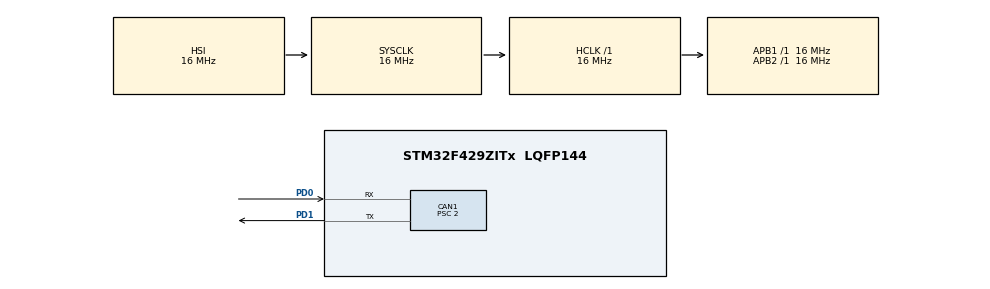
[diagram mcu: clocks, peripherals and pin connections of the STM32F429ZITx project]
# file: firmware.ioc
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CAN1.AutoBusOff=DISABLE
CAN1.AutoRetransmission=ENABLE
CAN1.AutoWakeUp=DISABLE
CAN1.BS1=CAN_BS1_13TQ
CAN1.BS2=CAN_BS2_2TQ
CAN1.CalculateBaudRate=500000
CAN1.CalculateTimeBit=2000
CAN1.CalculateTimeQuantum=125.0
CAN1.Prescaler=2
CAN1.ReceiveFifoLocked=DISABLE
CAN1.SyncJumpWidth=CAN_SJW_1TQ
CAN1.TimeTriggerMode=DISABLE
CAN1.TransmitFifoPriority=DISABLE
FREERTOS.Tasks01=defaultTask,24,128,StartDefaultTask,AS_EXTERNAL,NULL,0,defaultTaskBuffer,defaultTaskControlBlock
FREERTOS.Tasks02=canRxTask,32,256,StartCanRxTask,AS_EXTERNAL,NULL,0,canRxTaskBuffer,canRxTaskControlBlock
FREERTOS.Tasks03=canTxTask,32,256,StartCanTxTask,AS_EXTERNAL,NULL,0,canTxTaskBuffer,canTxTaskControlBlock
FREERTOS.configTOTAL_HEAP_SIZE=8192
Mcu.Family=STM32F4
Mcu.Name=STM32F429ZITx
Mcu.Package=LQFP144
NVIC.CAN1_RX0_IRQn=true\:5\:0\:true\:false\:true\:false\:true\:false\:true
NVIC.CAN1_TX_IRQn=true\:5\:0\:true\:false\:true\:false\:true\:false\:true
NVIC.PriorityGroup=NVIC_PRIORITYGROUP_4
PD0.Mode=CAN_Activate
PD0.Signal=CAN1_RX
PD1.Mode=CAN_Activate
PD1.Signal=CAN1_TX
ProjectManager.HeapSize=0x200
ProjectManager.StackSize=0x400
ProjectManager.TargetToolchain=STM32CubeIDE
RCC.AHBFreq_Value=16000000
RCC.APB1Freq_Value=16000000
RCC.APB2Freq_Value=16000000
RCC.CortexFreq_Value=16000000
RCC.HSE_VALUE=25000000
RCC.HSI_VALUE=16000000
RCC.LSE_VALUE=32768
RCC.SYSCLKFreq_VALUE=16000000
RCC.VCOOutputFreq_Value=192000000
VP_FREERTOS_VS_CMSIS_V1.Mode=CMSIS_V1
board=custom

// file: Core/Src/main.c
/* USER CODE BEGIN Header */
/**
  ******************************************************************************
  * @file           : main.c
  * @brief          : Main program body
  ******************************************************************************
  * @attention
  *
  * Copyright (c) 2026 STMicroelectronics.
  * All rights reserved.
  *
  * This software is licensed under terms that can be found in the LICENSE file
  * in the root directory of this software component.
  * If no LICENSE file comes with this software, it is provided AS-IS.
  *
  ******************************************************************************
  */
/* USER CODE END Header */
#include "main.h"
#include "cmsis_os.h"

/* USER CODE BEGIN Includes */
#include "queue.h"
/* USER CODE END Includes */

/* USER CODE BEGIN PTD */
/**
 * @brief  CAN frame descriptor exchanged through the inter-task queue.
 */
typedef struct
{
    uint32_t id;       /**< Standard (11-bit) or extended (29-bit) CAN ID */
    uint8_t  ide;      /**< 0 = standard, 1 = extended */
    uint8_t  dlc;      /**< Data-length code (0–8 bytes) */
    uint8_t  data[8];  /**< Payload */
} CAN_Msg_t;
/* USER CODE END PTD */

/* USER CODE BEGIN PD */
/** Number of CAN_Msg_t slots held in the receive queue */
#define CAN_QUEUE_LEN  10U
/** TX frame CAN standard ID */
#define CAN_TX_STD_ID  0x123U
/* USER CODE END PD */

CAN_HandleTypeDef hcan1;

osThreadId defaultTaskHandle;
uint32_t defaultTaskBuffer[ 128 ];
osStaticThreadDef_t defaultTaskControlBlock;
osThreadId canRxTaskHandle;
uint32_t canRxTaskBuffer[ 256 ];
osStaticThreadDef_t canRxTaskControlBlock;
/* USER CODE BEGIN PV */
/* ------------ CAN RX queue (ISR → canRxTask) ----------------------------- */
static QueueHandle_t canRxQueue;
static StaticQueue_t canRxQueueStruct;
static uint8_t       canRxQueueStorage[CAN_QUEUE_LEN * sizeof(CAN_Msg_t)];

osThreadId canTxTaskHandle;
uint32_t canTxTaskBuffer[ 256 ];
osStaticThreadDef_t canTxTaskControlBlock;
/* USER CODE END PV */

void SystemClock_Config(void);
static void MX_GPIO_Init(void);
static void MX_CAN1_Init(void);
void StartDefaultTask(void const * argument);
void StartCanRxTask(void const * argument);

/* USER CODE BEGIN PFP */
void StartCanTxTask(void const * argument);
/* USER CODE END PFP */

int main(void)
{

  /* MCU Configuration--------------------------------------------------------*/

  /* Reset of all peripherals, Initializes the Flash interface and the Systick. */
  HAL_Init();

  /* Configure the system clock */
  SystemClock_Config();

  /* Initialize all configured peripherals */
  MX_GPIO_Init();
  MX_CAN1_Init();

  /* USER CODE BEGIN RTOS_QUEUES */
  /* Create the RX queue with statically-allocated storage */
  canRxQueue = xQueueCreateStatic(CAN_QUEUE_LEN,
                                   sizeof(CAN_Msg_t),
                                   canRxQueueStorage,
                                   &canRxQueueStruct);
  configASSERT(canRxQueue != NULL);

  /* Enable RX-FIFO0 interrupt now that the queue exists */
  if (HAL_CAN_ActivateNotification(&hcan1, CAN_IT_RX_FIFO0_MSG_PENDING) != HAL_OK)
  {
    Error_Handler();
  }
  /* USER CODE END RTOS_QUEUES */

  /* Create the thread(s) */
  /* definition and creation of defaultTask */
  osThreadStaticDef(defaultTask, StartDefaultTask, osPriorityNormal, 0, 128, defaultTaskBuffer, &defaultTaskControlBlock);
  defaultTaskHandle = osThreadCreate(osThread(defaultTask), NULL);

  /* definition and creation of canRxTask */
  osThreadStaticDef(canRxTask, StartCanRxTask, osPriorityNormal, 0, 256, canRxTaskBuffer, &canRxTaskControlBlock);
  canRxTaskHandle = osThreadCreate(osThread(canRxTask), NULL);

  /* USER CODE BEGIN RTOS_THREADS */
  /* Create canTxTask through CMSIS-RTOS, matching firmware.ioc and the other tasks. */
  osThreadStaticDef(canTxTask, StartCanTxTask, osPriorityAboveNormal, 0, 256,
                    canTxTaskBuffer, &canTxTaskControlBlock);
  canTxTaskHandle = osThreadCreate(osThread(canTxTask), NULL);
  configASSERT(canTxTaskHandle != NULL);
  /* USER CODE END RTOS_THREADS */

  /* Start scheduler */
  osKernelStart();

  /* We should never get here as control is now taken by the scheduler */

  /* Infinite loop */
  while (1)
  {

  }
}

void SystemClock_Config(void)
{
  RCC_OscInitTypeDef RCC_OscInitStruct = {0};
  RCC_ClkInitTypeDef RCC_ClkInitStruct = {0};

  /** Configure the main internal regulator output voltage
  */
  __HAL_RCC_PWR_CLK_ENABLE();
  __HAL_PWR_VOLTAGESCALING_CONFIG(PWR_REGULATOR_VOLTAGE_SCALE3);

  /** Initializes the RCC Oscillators according to the specified parameters
  * in the RCC_OscInitTypeDef structure.
  */
  RCC_OscInitStruct.OscillatorType = RCC_OSCILLATORTYPE_HSI;
  RCC_OscInitStruct.HSIState = RCC_HSI_ON;
  RCC_OscInitStruct.HSICalibrationValue = RCC_HSICALIBRATION_DEFAULT;
  RCC_OscInitStruct.PLL.PLLState = RCC_PLL_NONE;
  if (HAL_RCC_OscConfig(&RCC_OscInitStruct) != HAL_OK)
  {
    Error_Handler();
  }

  /** Initializes the CPU, AHB and APB buses clocks
  */
  RCC_ClkInitStruct.ClockType = RCC_CLOCKTYPE_HCLK|RCC_CLOCKTYPE_SYSCLK
                              |RCC_CLOCKTYPE_PCLK1|RCC_CLOCKTYPE_PCLK2;
  RCC_ClkInitStruct.SYSCLKSource = RCC_SYSCLKSOURCE_HSI;
  RCC_ClkInitStruct.AHBCLKDivider = RCC_SYSCLK_DIV1;
  RCC_ClkInitStruct.APB1CLKDivider = RCC_HCLK_DIV1;
  RCC_ClkInitStruct.APB2CLKDivider = RCC_HCLK_DIV1;

  if (HAL_RCC_ClockConfig(&RCC_ClkInitStruct, FLASH_LATENCY_0) != HAL_OK)
  {
    Error_Handler();
  }
}

static void MX_CAN1_Init(void)
{

  hcan1.Instance = CAN1;
  hcan1.Init.Prescaler = 2;
  hcan1.Init.Mode = CAN_MODE_NORMAL;
  hcan1.Init.SyncJumpWidth = CAN_SJW_1TQ;
  hcan1.Init.TimeSeg1 = CAN_BS1_13TQ;
  hcan1.Init.TimeSeg2 = CAN_BS2_2TQ;
  hcan1.Init.TimeTriggeredMode = DISABLE;
  hcan1.Init.AutoBusOff = DISABLE;
  hcan1.Init.AutoWakeUp = DISABLE;
  hcan1.Init.AutoRetransmission = DISABLE;
  hcan1.Init.ReceiveFifoLocked = DISABLE;
  hcan1.Init.TransmitFifoPriority = DISABLE;
  if (HAL_CAN_Init(&hcan1) != HAL_OK)
  {
    Error_Handler();
  }
  /* USER CODE BEGIN CAN1_Init 2 */
  /* Accept-all pass-through filter → FIFO0 */
  {
    CAN_FilterTypeDef sFilter = {0};
    sFilter.FilterBank           = 0;
    sFilter.FilterMode           = CAN_FILTERMODE_IDMASK;
    sFilter.FilterScale          = CAN_FILTERSCALE_32BIT;
    sFilter.FilterIdHigh         = 0x0000U;
    sFilter.FilterIdLow          = 0x0000U;
    sFilter.FilterMaskIdHigh     = 0x0000U; /* mask 0 = accept all */
    sFilter.FilterMaskIdLow      = 0x0000U;
    sFilter.FilterFIFOAssignment = CAN_RX_FIFO0;
    sFilter.FilterActivation     = ENABLE;
    if (HAL_CAN_ConfigFilter(&hcan1, &sFilter) != HAL_OK) { Error_Handler(); }
  }
  if (HAL_CAN_Start(&hcan1) != HAL_OK) { Error_Handler(); }
  /* USER CODE END CAN1_Init 2 */

}

static void MX_GPIO_Init(void)
{

  /* GPIO Ports Clock Enable */
  __HAL_RCC_GPIOD_CLK_ENABLE();

}

/* USER CODE BEGIN 4 */

/**
 * @brief  CAN RX FIFO0 message-pending callback (called from ISR context).
 *
 *         Reads the incoming frame from the hardware and posts a CAN_Msg_t to
 *         canRxQueue so that StartCanRxTask can process it at task level.
 */
void HAL_CAN_RxFifo0MsgPendingCallback(CAN_HandleTypeDef *hcan)
{
  CAN_RxHeaderTypeDef rxHdr;
  CAN_Msg_t           msg;
  BaseType_t          xHigherPriorityTaskWoken = pdFALSE;

  if (HAL_CAN_GetRxMessage(hcan, CAN_RX_FIFO0, &rxHdr, msg.data) != HAL_OK)
  {
    return; /* Frame read error — discard */
  }

  if (rxHdr.IDE == CAN_ID_EXT)
  {
    msg.id  = rxHdr.ExtId;
    msg.ide = 1U;
  }
  else
  {
    msg.id  = rxHdr.StdId;
    msg.ide = 0U;
  }
  msg.dlc = (uint8_t)rxHdr.DLC;

  /* Post to the queue from ISR; yield if a higher-priority task was woken */
  xQueueSendFromISR(canRxQueue, &msg, &xHigherPriorityTaskWoken);
  portYIELD_FROM_ISR(xHigherPriorityTaskWoken);
}

/**
 * @brief  CAN TX task body — transmits a rolling-counter frame every 500 ms.
 *
 *         Waits for a free TX mailbox, builds an 8-byte payload with a 32-bit
 *         counter in the first four bytes (big-endian) followed by a fixed
 *         0xDEADBEEF pattern, and fires the frame at CAN_TX_STD_ID.
 */
void StartCanTxTask(void const * argument)
{
  (void)argument;

  CAN_TxHeaderTypeDef txHdr;
  uint8_t             txData[8];
  uint32_t            txMailbox;
  uint32_t            txCounter = 0U;

  txHdr.StdId              = CAN_TX_STD_ID;
  txHdr.ExtId              = 0x00000000U;
  txHdr.IDE                = CAN_ID_STD;
  txHdr.RTR                = CAN_RTR_DATA;
  txHdr.DLC                = 8U;
  txHdr.TransmitGlobalTime = DISABLE;

  for (;;)
  {
    /* Payload: 4-byte big-endian counter | 0xDEADBEEF signature */
    txData[0] = (uint8_t)(txCounter >> 24U);
    txData[1] = (uint8_t)(txCounter >> 16U);
    txData[2] = (uint8_t)(txCounter >>  8U);
    txData[3] = (uint8_t)(txCounter);
    txData[4] = 0xDEU;
    txData[5] = 0xADU;
    txData[6] = 0xBEU;
    txData[7] = 0xEFU;

    if (HAL_CAN_GetTxMailboxesFreeLevel(&hcan1) > 0U)
    {
      if (HAL_CAN_AddTxMessage(&hcan1, &txHdr, txData, &txMailbox) == HAL_OK)
      {
        txCounter++;
      }
    }

    osDelay(500); /* Transmit every 500 ms */
  }
}

/* USER CODE END 4 */

__weak void StartDefaultTask(void const * argument)
{
  /* USER CODE BEGIN 5 */
  /* Heartbeat — lowest-priority supervisor task */
  for (;;)
  {
    osDelay(1000); /* Yield every 1 s; extend with LED toggle or watchdog kick */
  }
  /* USER CODE END 5 */
}

void StartCanRxTask(void const * argument)
{
  /* USER CODE BEGIN StartCanRxTask */
  CAN_Msg_t rxMsg;

  for (;;)
  {
    /* Block indefinitely until HAL_CAN_RxFifo0MsgPendingCallback posts a frame */
    if (xQueueReceive(canRxQueue, &rxMsg, portMAX_DELAY) == pdTRUE)
    {
      /*
       * Application processing point.
       *
       * rxMsg.id      — CAN ID (standard or extended)
       * rxMsg.ide     — 0 = standard frame, 1 = extended frame
       * rxMsg.dlc     — number of valid bytes in rxMsg.data
       * rxMsg.data[]  — payload bytes [0 .. dlc-1]
       *
       * Example: add loopback, protocol dispatch, logging, etc.
       */
      (void)rxMsg; /* Remove this line and add real processing below */
    }
  }
  /* USER CODE END StartCanRxTask */
}

void Error_Handler(void)
{
  __disable_irq();
  while (1)
  {
  }
}
